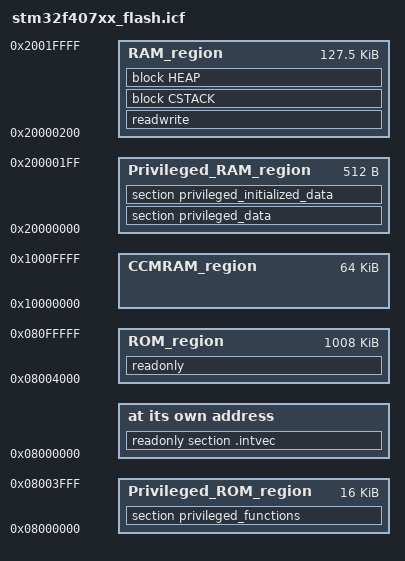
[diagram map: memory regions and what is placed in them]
/*###ICF### Section handled by ICF editor, don't touch! ****/
/*-Editor annotation file-*/
/* IcfEditorFile="$TOOLKIT_DIR$\config\ide\IcfEditor\cortex_v1_0.xml" */
/*-Specials-*/
define symbol __ICFEDIT_intvec_start__ = 0x08000000;
/*-Memory Regions-*/
define symbol __ICFEDIT_region_ROM_start__    = 0x08004000;
define symbol __ICFEDIT_region_ROM_end__      = 0x080FFFFF;
define symbol __ICFEDIT_region_Privileged_ROM_start__  = 0x08000000;
define symbol __ICFEDIT_region_Privileged_ROM_end__    = 0x08003FFF;
define symbol __ICFEDIT_region_RAM_start__    = 0x20000200;
define symbol __ICFEDIT_region_RAM_end__      = 0x2001FFFF;
define symbol __ICFEDIT_region_Privileged_RAM_start__    = 0x20000000;
define symbol __ICFEDIT_region_Privileged_RAM_end__      = 0x200001FF;
define symbol __ICFEDIT_region_CCMRAM_start__ = 0x10000000;
define symbol __ICFEDIT_region_CCMRAM_end__   = 0x1000FFFF;
/*-Sizes-*/
define symbol __ICFEDIT_size_cstack__ = 0x400;
define symbol __ICFEDIT_size_heap__   = 0x200;
/**** End of ICF editor section. ###ICF###*/


define memory mem with size = 4G;
define region ROM_region      = mem:[from __ICFEDIT_region_ROM_start__   to __ICFEDIT_region_ROM_end__];
define region Privileged_ROM_region      = mem:[from __ICFEDIT_region_Privileged_ROM_start__   to __ICFEDIT_region_Privileged_ROM_end__];
define region RAM_region      = mem:[from __ICFEDIT_region_RAM_start__   to __ICFEDIT_region_RAM_end__];
define region Privileged_RAM_region      = mem:[from __ICFEDIT_region_Privileged_RAM_start__   to __ICFEDIT_region_Privileged_RAM_end__];
define region CCMRAM_region   = mem:[from __ICFEDIT_region_CCMRAM_start__   to __ICFEDIT_region_CCMRAM_end__];

define block CSTACK    with alignment = 8, size = __ICFEDIT_size_cstack__   { };
define block HEAP      with alignment = 8, size = __ICFEDIT_size_heap__     { };

initialize by copy { readwrite };
do not initialize  { section .noinit };

place at address mem:__ICFEDIT_intvec_start__ { readonly section .intvec };

place in ROM_region   { readonly };
place in Privileged_ROM_region   {section privileged_functions };
place in Privileged_RAM_region   {section privileged_data, section privileged_initialized_data};
place in RAM_region   { readwrite, block CSTACK, block HEAP };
